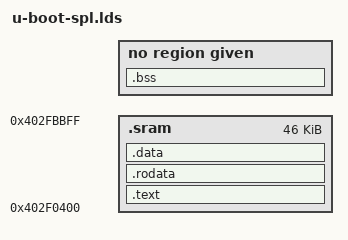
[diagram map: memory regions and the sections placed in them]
MEMORY { .sram : ORIGIN = 0x402F0400, LENGTH = (46 * 1024) }
MEMORY { .sdram : ORIGIN = 0x80000000, LENGTH = 0x80000 }
OUTPUT_FORMAT("elf32-littlearm", "elf32-littlearm", "elf32-littlearm")
OUTPUT_ARCH(arm)
ENTRY(_start)
SECTIONS
{
 .text :
 {
 __start = .;
   arch/arm/cpu/armv7/start.o (.text)
   *(.text*)
 } >.sram
 . = ALIGN(4);
 .rodata : { *(SORT_BY_ALIGNMENT(.rodata*)) } >.sram
 . = ALIGN(4);
 .data : { *(SORT_BY_ALIGNMENT(.data*)) } >.sram
 . = ALIGN(4);
 __image_copy_end = .;
 _end = .;
 .bss :
 {
  . = ALIGN(4);
  __bss_start = .;
  *(.bss*)
  . = ALIGN(4);
  __bss_end__ = .;
 } >.sdram
}
